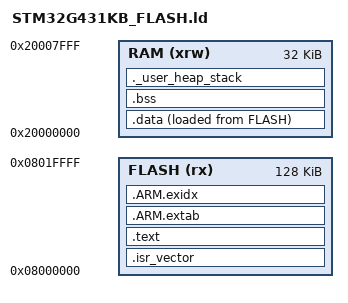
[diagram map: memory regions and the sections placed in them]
ENTRY(Reset_Handler)

MEMORY
{
  FLASH (rx)  : ORIGIN = 0x08000000, LENGTH = 128K
  RAM   (xrw) : ORIGIN = 0x20000000, LENGTH = 32K
}

_estack = ORIGIN(RAM) + LENGTH(RAM);

SECTIONS
{
  .isr_vector :
  {
    KEEP(*(.isr_vector))
  } > FLASH

  .text :
  {
    *(.text*)
    *(.rodata*)
    KEEP(*(.init))
    KEEP(*(.fini))
    . = ALIGN(4);
  } > FLASH

  .ARM.extab :
  {
    *(.ARM.extab* .gnu.linkonce.armextab.*)
  } > FLASH

  .ARM.exidx :
  {
    __exidx_start = .;
    *(.ARM.exidx* .gnu.linkonce.armexidx.*)
    __exidx_end = .;
  } > FLASH

  _sidata = LOADADDR(.data);

  .data :
  {
    _sdata = .;
    *(.data*)
    . = ALIGN(4);
    _edata = .;
  } > RAM AT > FLASH

  .bss :
  {
    _sbss = .;
    *(.bss*)
    *(COMMON)
    . = ALIGN(4);
    _ebss = .;
  } > RAM

  ._user_heap_stack :
  {
    . = ALIGN(8);
    PROVIDE(end = .);
    PROVIDE(_end = .);
    . = . + 0x400;
    . = . + 0x800;
    . = ALIGN(8);
  } > RAM
}
